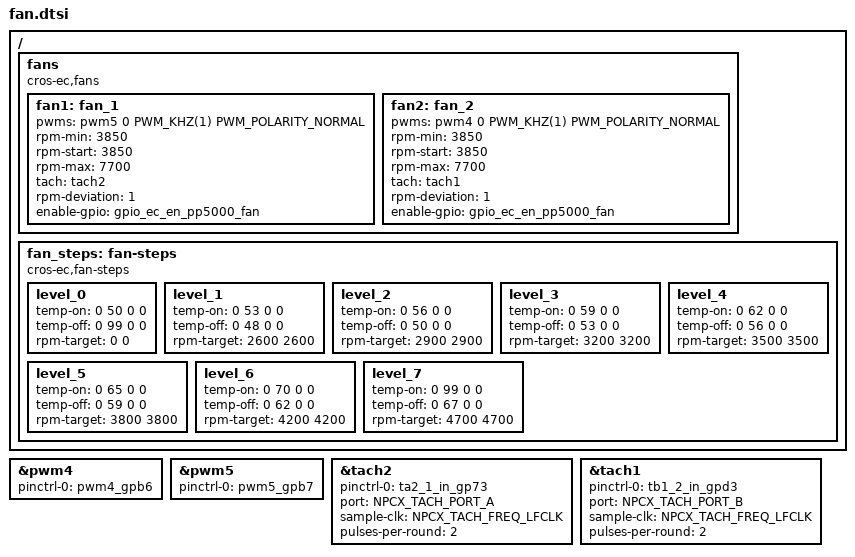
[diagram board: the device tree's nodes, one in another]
/* Copyright 2025 The ChromiumOS Authors
 * Use of this source code is governed by a BSD-style license that can be
 * found in the LICENSE file.
 */

/ {
	fans {
		compatible = "cros-ec,fans";

		/* TODO: update the fan params */
		fan1: fan_1 {
			pwms = <&pwm5 0 PWM_KHZ(1) PWM_POLARITY_NORMAL>;
			rpm-min = <3850>;
			rpm-start = <3850>;
			rpm-max = <7700>;
			tach = <&tach2>;
			rpm-deviation = <1>;
			enable-gpio = <&gpio_ec_en_pp5000_fan>;
		};
		fan2: fan_2 {
			pwms = <&pwm4 0 PWM_KHZ(1) PWM_POLARITY_NORMAL>;
			rpm-min = <3850>;
			rpm-start = <3850>;
			rpm-max = <7700>;
			tach = <&tach1>;
			rpm-deviation = <1>;
			enable-gpio = <&gpio_ec_en_pp5000_fan>;
		};

	};

	fan_steps: fan-steps {
		compatible = "cros-ec,fan-steps";
		level_0 {
			temp-on = <0 50 0 0>;
			temp-off = <0 99 0 0>;
			rpm-target = <0 0>;
		};
		level_1 {
			temp-on = <0 53 0 0>;
			temp-off = <0 48 0 0>;
			rpm-target = <2600 2600>;
		};
		level_2 {
			temp-on = <0 56 0 0>;
			temp-off = <0 50 0 0>;
			rpm-target = <2900 2900>;
		};
		level_3 {
			temp-on = <0 59 0 0>;
			temp-off = <0 53 0 0>;
			rpm-target = <3200 3200>;
		};
		level_4 {
			temp-on = <0 62 0 0>;
			temp-off = <0 56 0 0>;
			rpm-target = <3500 3500>;
		};
		level_5 {
			temp-on = <0 65 0 0>;
			temp-off = <0 59 0 0>;
			rpm-target = <3800 3800>;
		};
		level_6 {
			temp-on = <0 70 0 0>;
			temp-off = <0 62 0 0>;
			rpm-target = <4200 4200>;
		};
		level_7 {
			temp-on = <0 99 0 0>;
			temp-off = <0 67 0 0>;
			rpm-target = <4700 4700>;
		};
	};
};

&pwm4 {
	status = "okay";
	pinctrl-0 = <&pwm4_gpb6>;
	pinctrl-names = "default";
};

&pwm5 {
	status = "okay";
	pinctrl-0 = <&pwm5_gpb7>;
	pinctrl-names = "default";
};

&tach2 {
	status = "okay";
	pinctrl-0 = <&ta2_1_in_gp73>;
	pinctrl-names = "default";
	port = <NPCX_TACH_PORT_A>;
	sample-clk = <NPCX_TACH_FREQ_LFCLK>;
	pulses-per-round = <2>;
};

&tach1 {
	status = "okay";
	pinctrl-0 = <&tb1_2_in_gpd3>;
	pinctrl-names = "default";
	port = <NPCX_TACH_PORT_B>;
	sample-clk = <NPCX_TACH_FREQ_LFCLK>;
	pulses-per-round = <2>;
};
